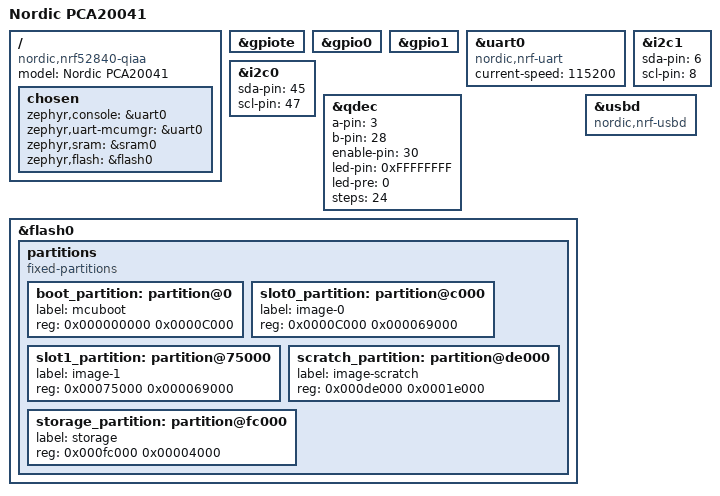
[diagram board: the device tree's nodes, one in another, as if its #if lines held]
/*
 * Copyright (c) 2018 Nordic Semiconductor ASA
 *
 * SPDX-License-Identifier: BSD-5-Clause-Nordic
 */

/dts-v1/;
#include <nordic/nrf52840.dtsi>

/ {
	model = "Nordic PCA20041";
	compatible = "nordic,nrf52840-qiaa",
		     "nordic,nrf52840";

	chosen {
		zephyr,console = &uart0;
#ifdef CONFIG_MCUMGR_SMP_UART
		zephyr,uart-mcumgr = &uart0;
#endif
		zephyr,sram = &sram0;
		zephyr,flash = &flash0;
	};
};

&gpiote {
	status ="ok";
};

&gpio0 {
	status ="ok";
};

&gpio1 {
	status ="ok";
};

&uart0 {
	status = "ok";
	compatible = "nordic,nrf-uart";
	current-speed = <115200>;
};

&i2c0 {
	status = "ok";
	sda-pin = <45>;
	scl-pin = <47>;
};

&i2c1 {
	status = "ok";
	sda-pin = <6>;
	scl-pin = <8>;
};

&qdec {
	status = "ok";
	a-pin = <3>;
	b-pin = <28>;
	enable-pin = <30>;
	led-pin = <0xFFFFFFFF>;
	led-pre = <0>;
	steps = <24>;
};

&flash0 {
	/*
	 * For more information, see:
	 * http://docs.zephyrproject.org/devices/dts/flash_partitions.html
	 */
	partitions {
		compatible = "fixed-partitions";
		#address-cells = <1>;
		#size-cells = <1>;

		boot_partition: partition@0 {
			label = "mcuboot";
			reg = <0x000000000 0x0000C000>;
		};
		slot0_partition: partition@c000 {
			label = "image-0";
			reg = <0x0000C000 0x000069000>;
		};
		slot1_partition: partition@75000 {
			label = "image-1";
			reg = <0x00075000 0x000069000>;
		};
		scratch_partition: partition@de000 {
			label = "image-scratch";
			reg = <0x000de000 0x0001e000>;
		};

#if defined(CONFIG_FS_FLASH_STORAGE_PARTITION)
		storage_partition: partition@fc000 {
			label = "storage";
			reg = <0x000fc000 0x00004000>;
		};
#endif
	};
};

&usbd {
	compatible = "nordic,nrf-usbd";
	status = "ok";
};
